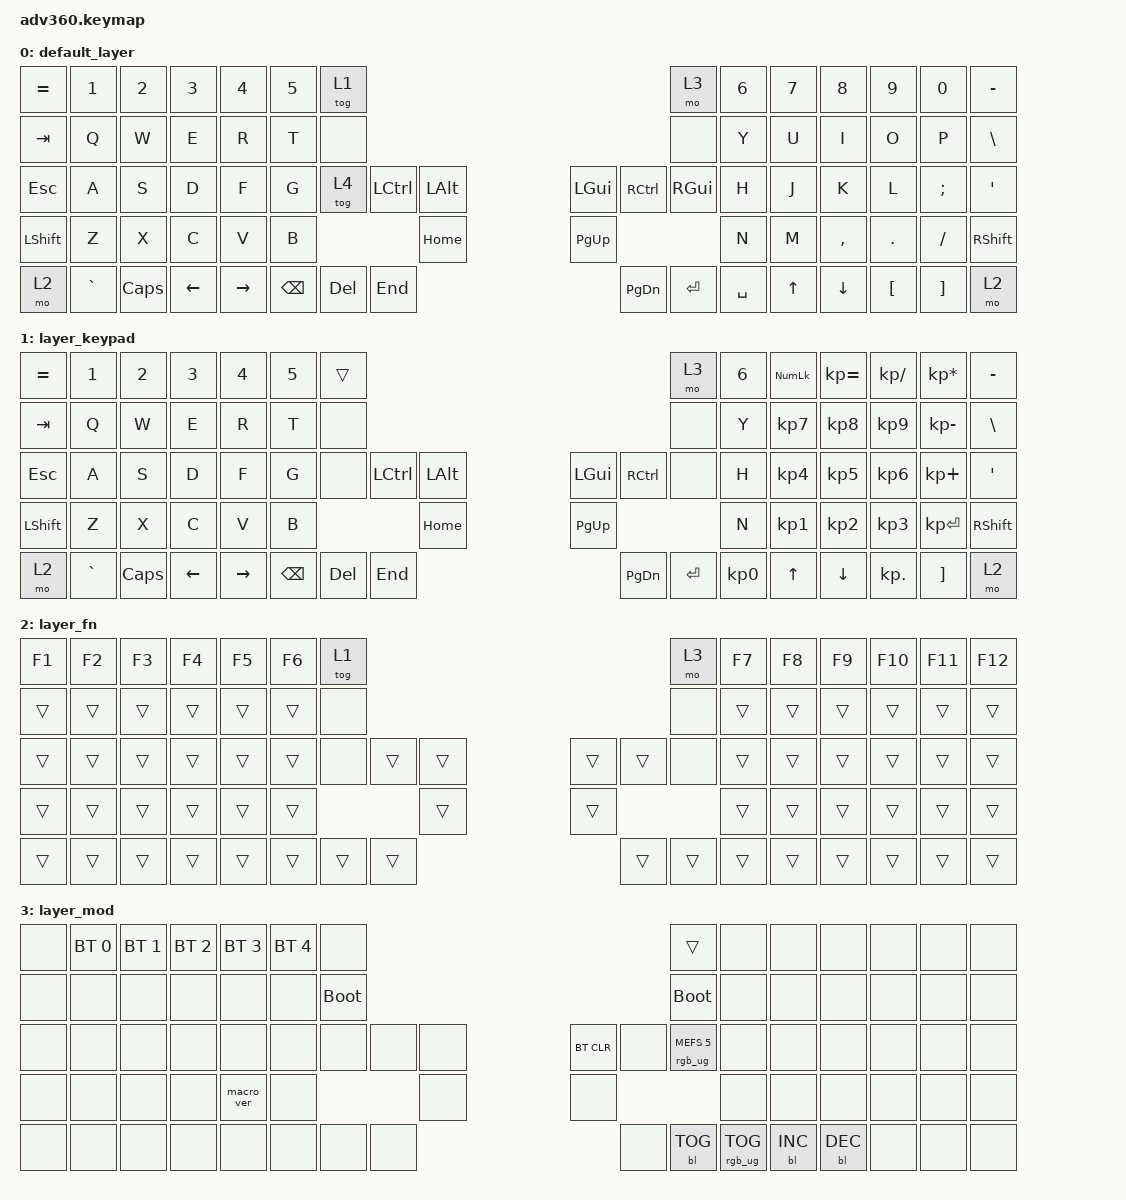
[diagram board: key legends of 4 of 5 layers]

/*
 * Copyright (c) 2020 The ZMK Contributors
 *
 * SPDX-License-Identifier: MIT
 */


/* THIS FILE WAS GENERATED!
 *
 * This file was generated automatically. You may or may not want to
 * edit it directly.
 */

/* 마우스 기본 속도 및 스크롤 속도 설정 */
#define ZMK_POINTING_DEFAULT_MOVE_VAL 1500  // 커서 이동 속도 기본값 (기본: 600)
#define ZMK_POINTING_DEFAULT_SCRL_VAL 20    // 스크롤 속도 기본값 (기본: 10)

/* 헤더 파일 포함 - 다른 저장소에서 복사해옴 */
#include "pointing.h"



#include <behaviors.dtsi>
#include <dt-bindings/zmk/keys.h>
#include <dt-bindings/zmk/bt.h>
#include <dt-bindings/zmk/rgb.h>
#include <dt-bindings/zmk/backlight.h>

/ {
  behaviors {
    #include "macros.dtsi"
    #include "version.dtsi"

    hm: homerow_mods {
        compatible = "zmk,behavior-hold-tap";
        label = "HOMEROW_MODS";
        #binding-cells = <2>;
        tapping-term-ms = <200>;
        quick_tap_ms = <175>;
        flavor = "tap-preferred";
        bindings = <&kp>, <&kp>;
    };


    /* 마우스 동작 정의 */
 
    pointing_scroll: pointing_scroll {
        compatible = "zmk,behavior-scroll";
        #binding-cells = <0>;
    };

    pointing_move: pointing_move {
        compatible = "zmk,behavior-move";
        #binding-cells = <0>;
    };

    pointing_button: pointing_button {
        compatible = "zmk,behavior-button";
        #binding-cells = <0>;
    };

    pointing_speed_decrease: pointing_speed_decrease {
        compatible = "zmk,behavior-speed-decrease";
        #binding-cells = <0>;
    };

    pointing_speed_increase: pointing_speed_increase {
        compatible = "zmk,behavior-speed-increase";
        #binding-cells = <0>;
    };

  };






    keymap {
        compatible = "zmk,keymap";


        default_layer {
            bindings = <
 &kp EQUAL     &kp N1    &kp N2    &kp N3     &kp N4  &kp N5              &tog 1                                                                 &mo 3  &kp N6  &kp N7     &kp N8    &kp N9    &kp N0  &kp MINUS
   &kp TAB      &kp Q     &kp W     &kp E      &kp R   &kp T               &none                                                                 &none   &kp Y   &kp U      &kp I     &kp O     &kp P   &kp BSLH
   &kp ESC      &kp A     &kp S     &kp D      &kp F   &kp G               &tog 4  &kp LCTRL  &kp LALT                   &kp LGUI  &kp RCTRL      &kp RGUI   &kp H   &kp J      &kp K     &kp L  &kp SEMI    &kp SQT
 &kp LSHFT      &kp Z     &kp X     &kp C      &kp V   &kp B                                 &kp HOME                  &kp PG_UP                         &kp N   &kp M  &kp COMMA   &kp DOT  &kp FSLH  &kp RSHFT
     &mo 2  &kp GRAVE  &kp CAPS  &kp LEFT  &kp RIGHT                    &kp BSPC    &kp DEL   &kp END                  &kp PG_DN  &kp ENTER  &kp SPACE          &kp UP   &kp DOWN  &kp LBKT  &kp RBKT      &mo 2
            >;
        };

        layer_keypad {
            bindings = <
 &kp EQUAL     &kp N1    &kp N2    &kp N3     &kp N4  &kp N5              &trans                                                                 &mo 3  &kp N6  &kp KP_NUM  &kp KP_EQUAL  &kp KP_DIVIDE  &kp KP_MULTIPLY  &kp MINUS
   &kp TAB      &kp Q     &kp W     &kp E      &kp R   &kp T               &none                                                                 &none   &kp Y   &kp KP_N7     &kp KP_N8      &kp KP_N9     &kp KP_MINUS   &kp BSLH
   &kp ESC      &kp A     &kp S     &kp D      &kp F   &kp G               &none  &kp LCTRL  &kp LALT                   &kp LGUI  &kp RCTRL      &none   &kp H   &kp KP_N4     &kp KP_N5      &kp KP_N6      &kp KP_PLUS    &kp SQT
 &kp LSHFT      &kp Z     &kp X     &kp C      &kp V   &kp B                                 &kp HOME                  &kp PG_UP                         &kp N   &kp KP_N1     &kp KP_N2      &kp KP_N3     &kp KP_ENTER  &kp RSHFT
     &mo 2  &kp GRAVE  &kp CAPS  &kp LEFT  &kp RIGHT                    &kp BSPC    &kp DEL   &kp END                  &kp PG_DN  &kp ENTER  &kp KP_N0              &kp UP      &kp DOWN     &kp KP_DOT         &kp RBKT      &mo 2
            >;
        };

        layer_fn {
            bindings = <
 &kp F1  &kp F2  &kp F3  &kp F4  &kp F5  &kp F6            &tog 1                                                   &mo 3  &kp F7  &kp F8  &kp F9  &kp F10  &kp F11  &kp F12
 &trans  &trans  &trans  &trans  &trans  &trans             &none                                                   &none  &trans  &trans  &trans   &trans   &trans   &trans
 &trans  &trans  &trans  &trans  &trans  &trans             &none  &trans  &trans                  &trans  &trans   &none  &trans  &trans  &trans   &trans   &trans   &trans
 &trans  &trans  &trans  &trans  &trans  &trans                            &trans                  &trans                  &trans  &trans  &trans   &trans   &trans   &trans
 &trans  &trans  &trans  &trans  &trans                    &trans  &trans  &trans                  &trans  &trans  &trans          &trans  &trans   &trans   &trans   &trans
            >;
        };

        layer_mod {
            bindings = <
  &none  &bt BT_SEL 0  &bt BT_SEL 1  &bt BT_SEL 2  &bt BT_SEL 3  &bt BT_SEL 4                  &none                                                                          &trans   &none       &none       &none   &none   &none   &none
  &none         &none         &none         &none         &none         &none            &bootloader                                                                     &bootloader   &none       &none       &none   &none   &none   &none
  &none         &none         &none         &none         &none         &none                  &none   &none   &none                  &bt BT_CLR       &none  &rgb_ug RGB_MEFS_CMD 5   &none       &none       &none   &none   &none   &none
  &none         &none         &none         &none    &macro_ver         &none                                  &none                       &none                                       &none       &none       &none   &none   &none   &none
  &none         &none         &none         &none         &none                                &none   &none   &none                       &none  &bl BL_TOG         &rgb_ug RGB_TOG          &bl BL_INC  &bl BL_DEC   &none   &none   &none
            >;
        };

        layer_Mouse {
            bindings = <
  &none       &none       &none         &pointing_scroll SCRL_DOWN   &none        &none          &none                                     &none    &none       &none       &none    &none    &none    &none
  &none       &none       &pointing_button MB3  &none  &none       &none          &none                                     &none    &none       &none       &none    &none    &none    &none
  &none       &pointing_speed_decrease   &pointing_speed_increase   &pointing_button MB2  &pointing_button MB1  &pointing_button MB3  &none    &none    &none          &none    &none    &none    &none
  &none       &none       &none         &none         &none        &none                            &none                              &none                              &pointing_move MOVE_UP  &pointing_move MOVE_LEFT  &pointing_move MOVE_RIGHT  &pointing_move MOVE_DOWN  &none    &none    &none
  &none       &none       &none         &none         &none        &none       &none         &none                  &none         &pointing_scroll SCRL_UP   &none       &none    &none    &none    &none    &none
            >;
        };





    };
};
